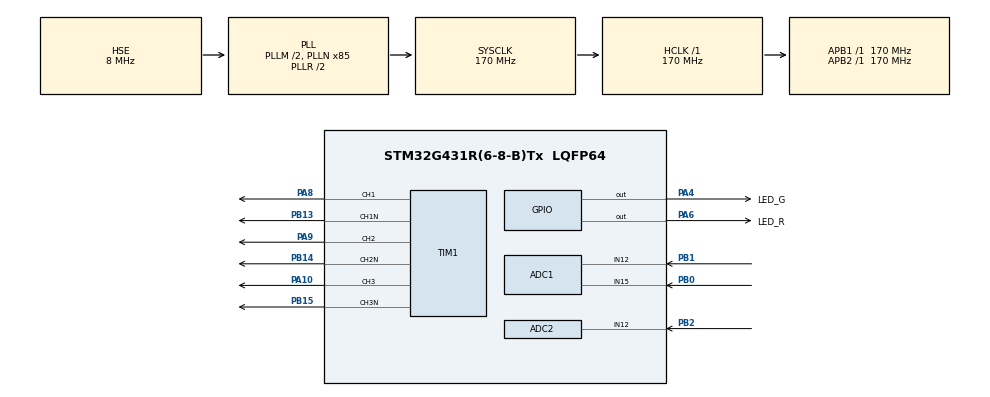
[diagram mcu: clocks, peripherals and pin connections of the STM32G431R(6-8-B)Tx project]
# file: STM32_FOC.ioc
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ADC1.Channel-1\#ChannelRegularConversion=ADC_CHANNEL_12
ADC1.NbrOfConversionFlag=1
ADC1.OffsetNumber-1\#ChannelRegularConversion=ADC_OFFSET_NONE
ADC1.Rank-1\#ChannelRegularConversion=1
ADC1.SamplingTime-1\#ChannelRegularConversion=ADC_SAMPLETIME_2CYCLES_5
ADC1.master=1
ADC2.Channel-0\#ChannelRegularConversion=ADC_CHANNEL_12
ADC2.NbrOfConversionFlag=1
ADC2.OffsetNumber-0\#ChannelRegularConversion=ADC_OFFSET_NONE
ADC2.Rank-0\#ChannelRegularConversion=1
ADC2.SamplingTime-0\#ChannelRegularConversion=ADC_SAMPLETIME_2CYCLES_5
Mcu.Family=STM32G4
Mcu.Name=STM32G431R(6-8-B)Tx
Mcu.Package=LQFP64
NVIC.PriorityGroup=NVIC_PRIORITYGROUP_4
PA10.Signal=S_TIM1_CH3
PA13.Mode=Trace_Asynchronous_SW
PA13.Signal=SYS_JTMS-SWDIO
PA14.Mode=Trace_Asynchronous_SW
PA14.Signal=SYS_JTCK-SWCLK
PA4.GPIO_Label=LED_G
PA4.Signal=GPIO_Output
PA6.GPIO_Label=LED_R
PA6.Signal=GPIO_Output
PA8.Signal=S_TIM1_CH1
PA9.Signal=S_TIM1_CH2
PB0.Mode=IN15-Single-Ended
PB0.Signal=ADC1_IN15
PB1.Mode=IN12-Single-Ended
PB1.Signal=ADC1_IN12
PB13.Mode=PWM Generation1 CH1 CH1N
PB13.Signal=TIM1_CH1N
PB14.Mode=PWM Generation2 CH2 CH2N
PB14.Signal=TIM1_CH2N
PB15.Mode=PWM Generation3 CH3 CH3N
PB15.Signal=TIM1_CH3N
PB2.Mode=IN12-Single-Ended
PB2.Signal=ADC2_IN12
PB3.Mode=Trace_Asynchronous_SW
PB3.Signal=SYS_JTDO-SWO
PF0-OSC_IN.Mode=HSE-External-Oscillator
PF0-OSC_IN.Signal=RCC_OSC_IN
PF1-OSC_OUT.Mode=HSE-External-Oscillator
PF1-OSC_OUT.Signal=RCC_OSC_OUT
ProjectManager.HeapSize=0x200
ProjectManager.StackSize=0x400
ProjectManager.TargetToolchain=STM32CubeIDE
RCC.ADC12Freq_Value=170000000
RCC.AHBFreq_Value=170000000
RCC.APB1Freq_Value=170000000
RCC.APB1TimFreq_Value=170000000
RCC.APB2Freq_Value=170000000
RCC.APB2TimFreq_Value=170000000
RCC.CortexFreq_Value=170000000
RCC.EXTERNAL_CLOCK_VALUE=12288000
RCC.HCLKFreq_Value=170000000
RCC.HSE_VALUE=8000000
RCC.HSI48_VALUE=48000000
RCC.HSI_VALUE=16000000
RCC.LSE_VALUE=32768
RCC.PLLM=RCC_PLLM_DIV2
RCC.PLLN=85
RCC.PLLSourceVirtual=RCC_PLLSOURCE_HSE
RCC.SYSCLKFreq_VALUE=170000000
RCC.SYSCLKSource=RCC_SYSCLKSOURCE_PLLCLK
RCC.USBFreq_Value=170000000
RCC.VCOOutputFreq_Value=340000000
SH.S_TIM1_CH1.0=TIM1_CH1,PWM Generation1 CH1 CH1N
SH.S_TIM1_CH2.0=TIM1_CH2,PWM Generation2 CH2 CH2N
SH.S_TIM1_CH3.0=TIM1_CH3,PWM Generation3 CH3 CH3N
TIM1.AutoReloadPreload=TIM_AUTORELOAD_PRELOAD_ENABLE
TIM1.BreakState=TIM_BREAK_DISABLE
TIM1.Channel-PWM\ Generation1\ CH1\ CH1N=TIM_CHANNEL_1
TIM1.Channel-PWM\ Generation2\ CH2\ CH2N=TIM_CHANNEL_2
TIM1.Channel-PWM\ Generation3\ CH3\ CH3N=TIM_CHANNEL_3
TIM1.DeadTimePreload=ENABLE
TIM1.OCFastMode_PWM-PWM\ Generation1\ CH1\ CH1N=TIM_OCFAST_DISABLE
TIM1.OffStateIDLEMode=TIM_OSSI_ENABLE
TIM1.OffStateRunMode=TIM_OSSR_ENABLE
TIM1.TIM_MasterSlaveMode=TIM_MASTERSLAVEMODE_DISABLE
VP_SYS_VS_DBSignals.Mode=DisableDeadBatterySignals
VP_TIM1_VS_ClockSourceINT.Mode=Internal
board=custom

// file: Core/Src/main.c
/* USER CODE BEGIN Header */
/**
  ******************************************************************************
  * @file           : main.c
  * @brief          : Main program body
  ******************************************************************************
  * @attention
  *
  * Copyright (c) 2024 STMicroelectronics.
  * All rights reserved.
  *
  * This software is licensed under terms that can be found in the LICENSE file
  * in the root directory of this software component.
  * If no LICENSE file comes with this software, it is provided AS-IS.
  *
  ******************************************************************************
  */
/* USER CODE END Header */
#include "main.h"
#include "adc.h"
#include "tim.h"
#include "gpio.h"

/* USER CODE BEGIN PV */
float Var1 = 0.0;
float time_step = 0.001f;

unsigned int tim_cnt = 0;

/* USER CODE END PV */

void SystemClock_Config(void);

/* USER CODE BEGIN 0 */

int _write(int file , char *ptr,int len)
{
    int DataIdx;
    for(DataIdx = 0;DataIdx<len;DataIdx++){
        ITM_SendChar(*ptr++);
    }
    return len;
}

/* USER CODE END 0 */

int main(void)
{

  /* MCU Configuration--------------------------------------------------------*/

  /* Reset of all peripherals, Initializes the Flash interface and the Systick. */
  HAL_Init();

  /* Configure the system clock */
  SystemClock_Config();

  /* Initialize all configured peripherals */
  MX_GPIO_Init();
  MX_ADC1_Init();
  MX_TIM1_Init();
  MX_ADC2_Init();

  /* Infinite loop */
  while (1)
  {

    /* USER CODE BEGIN 3 */
	  HAL_Delay(100);
	  time_step += 0.001f;
	  Var1 = sin(0.1*time_step*6.0);
	  tim_cnt++;

	  printf("SWO TEST  %d \r\n",tim_cnt);

  }
  /* USER CODE END 3 */
}

void SystemClock_Config(void)
{
  RCC_OscInitTypeDef RCC_OscInitStruct = {0};
  RCC_ClkInitTypeDef RCC_ClkInitStruct = {0};

  /** Configure the main internal regulator output voltage
  */
  HAL_PWREx_ControlVoltageScaling(PWR_REGULATOR_VOLTAGE_SCALE1_BOOST);

  /** Initializes the RCC Oscillators according to the specified parameters
  * in the RCC_OscInitTypeDef structure.
  */
  RCC_OscInitStruct.OscillatorType = RCC_OSCILLATORTYPE_HSE;
  RCC_OscInitStruct.HSEState = RCC_HSE_ON;
  RCC_OscInitStruct.PLL.PLLState = RCC_PLL_ON;
  RCC_OscInitStruct.PLL.PLLSource = RCC_PLLSOURCE_HSE;
  RCC_OscInitStruct.PLL.PLLM = RCC_PLLM_DIV2;
  RCC_OscInitStruct.PLL.PLLN = 85;
  RCC_OscInitStruct.PLL.PLLP = RCC_PLLP_DIV2;
  RCC_OscInitStruct.PLL.PLLQ = RCC_PLLQ_DIV2;
  RCC_OscInitStruct.PLL.PLLR = RCC_PLLR_DIV2;
  if (HAL_RCC_OscConfig(&RCC_OscInitStruct) != HAL_OK)
  {
    Error_Handler();
  }

  /** Initializes the CPU, AHB and APB buses clocks
  */
  RCC_ClkInitStruct.ClockType = RCC_CLOCKTYPE_HCLK|RCC_CLOCKTYPE_SYSCLK
                              |RCC_CLOCKTYPE_PCLK1|RCC_CLOCKTYPE_PCLK2;
  RCC_ClkInitStruct.SYSCLKSource = RCC_SYSCLKSOURCE_PLLCLK;
  RCC_ClkInitStruct.AHBCLKDivider = RCC_SYSCLK_DIV1;
  RCC_ClkInitStruct.APB1CLKDivider = RCC_HCLK_DIV1;
  RCC_ClkInitStruct.APB2CLKDivider = RCC_HCLK_DIV1;

  if (HAL_RCC_ClockConfig(&RCC_ClkInitStruct, FLASH_LATENCY_4) != HAL_OK)
  {
    Error_Handler();
  }
}

void Error_Handler(void)
{
  __disable_irq();
  while (1)
  {
  }
}
